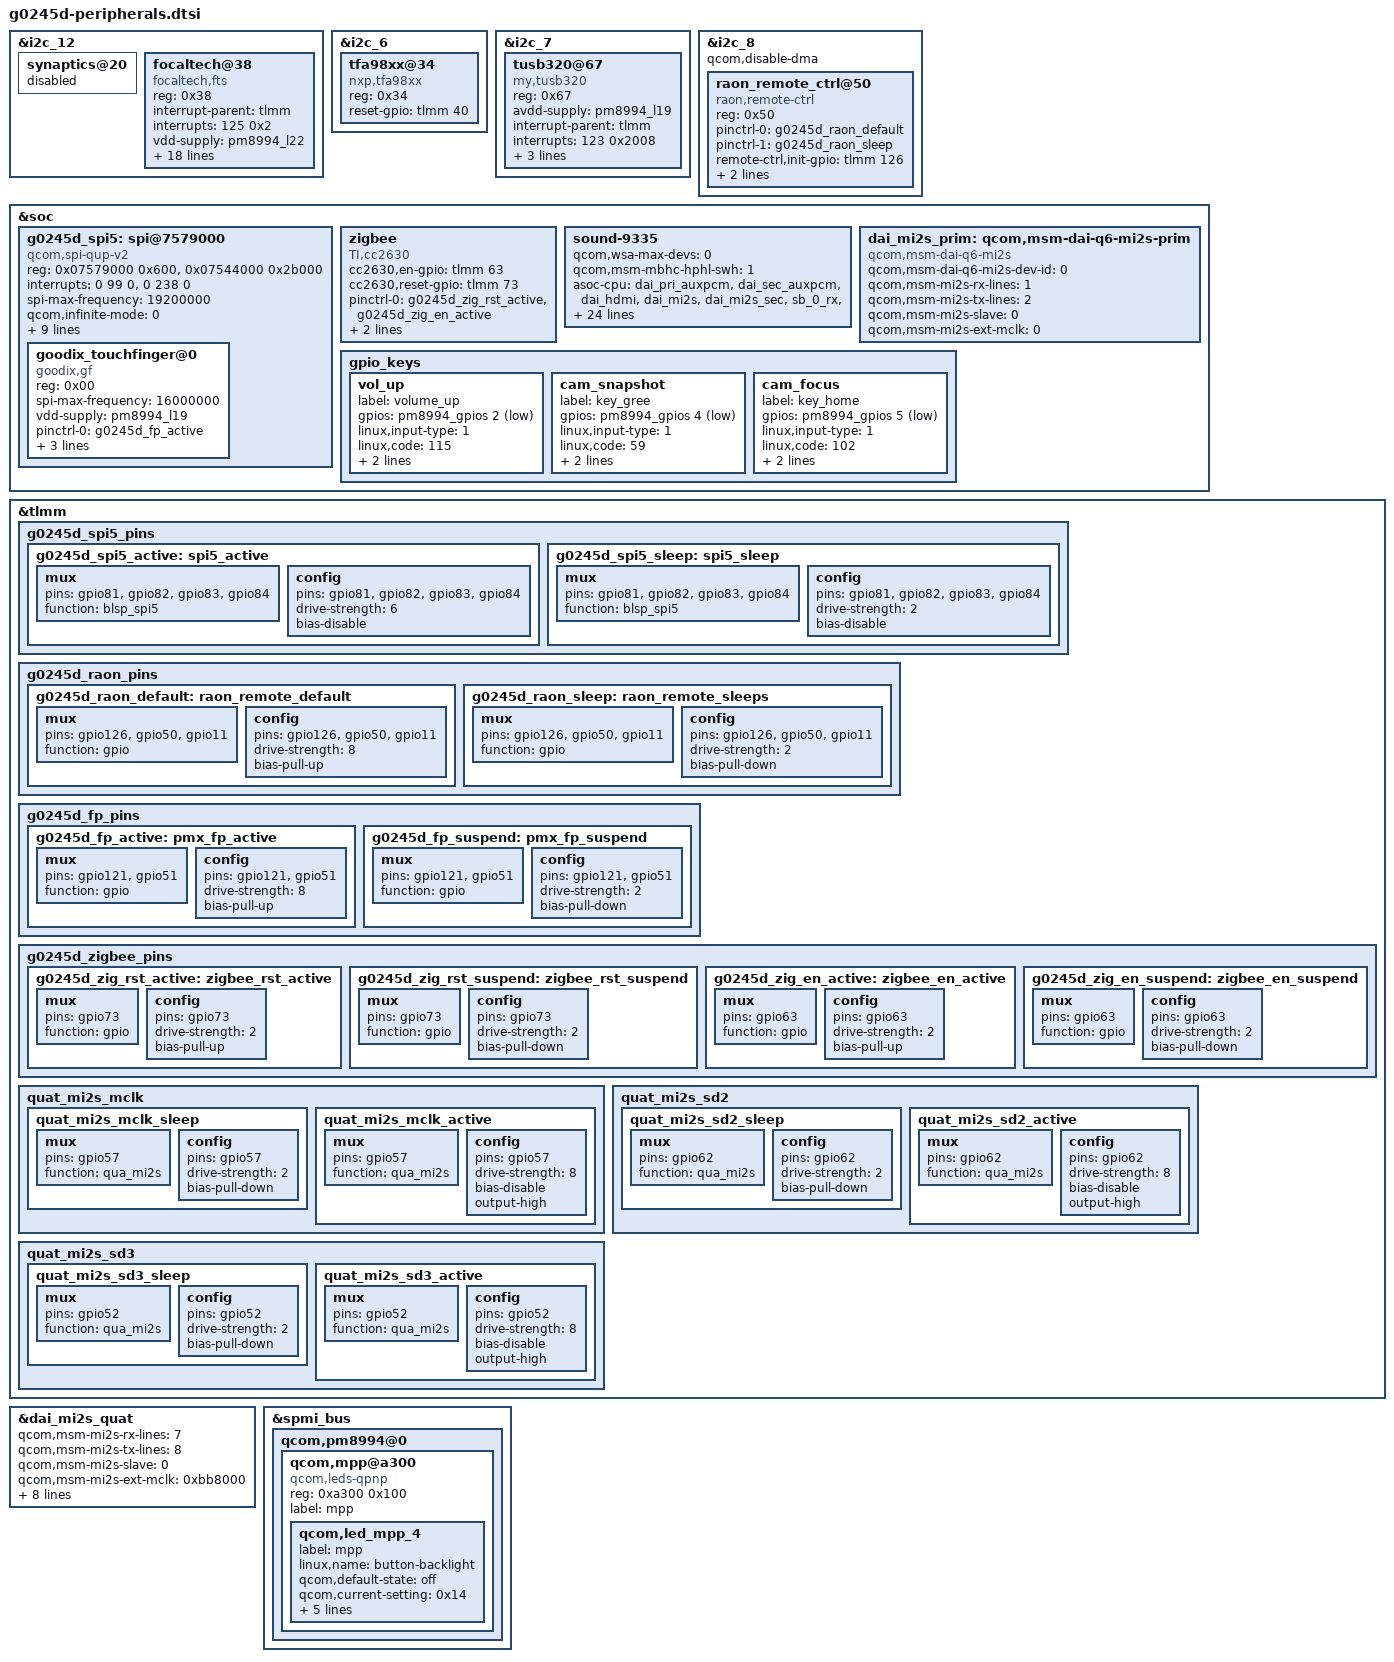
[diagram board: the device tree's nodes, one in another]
/*
 * Gree G0245D private peripheral device-tree nodes.
 *
 * Contract source: work/stock-044.dts (the DTB actually selected by the
 * G0245D bootloader) and 3.18/kernel-g0245d-cm13/Documentation/g0245d/
 * peripherals.md.  Numeric phandles were resolved to 4.4 labels; the
 * pinctrl states are newly declared here because the 4.4 MTP dtsi only
 * carries ts_active/ts_suspend.
 *
 * This file is purely additive: it never overrides a panel or WLAN node.
 */

&i2c_12 {
	/* The inherited 4.4 MTP dtsi declares a Synaptics DSX touch at 0x20 on
	 * this bus, and mi8996_defconfig enables that driver. G0245D only has
	 * the FT8716 at 0x38; both nodes would otherwise claim GPIO 125 for the
	 * touch IRQ. Disable it here so the upstream dtsi stays untouched.
	 */
	synaptics@20 {
		status = "disabled";
	};

	focaltech@38 {
		compatible = "focaltech,fts";
		reg = <0x38>;
		interrupt-parent = <&tlmm>;
		interrupts = <125 0x2>;
		vdd-supply = <&pm8994_l22>;
		vcc_i2c-supply = <&pm8994_l14>;
		pinctrl-names = "pmx_ts_active", "pmx_ts_suspend";
		pinctrl-0 = <&ts_active>;
		pinctrl-1 = <&ts_suspend>;
		focaltech,name = "fts";
		focaltech,family-id = <0x54>;
		focaltech,reset-gpio = <&tlmm 89 0x00>;
		focaltech,irq-gpio = <&tlmm 125 0x02>;
		focaltech,display-coords = <0 0 1080 1920>;
		focaltech,panel-coords = <0 0 1080 1920>;
		focaltech,button-map = <0x46 0x96 0x38b>;
		focaltech,no-force-update;
		focaltech,i2c-pull-up;
		focaltech,group-id = <0x01>;
		focaltech,hard-reset-delay-ms = <0x14>;
		focaltech,soft-reset-delay-ms = <0x96>;
		focaltech,num-max-touches = <0x0a>;
		focaltech,fw-name = "FT8716_FW_Reference_V0A_D01_20170227_app.i";
	};
};

&i2c_6 {
	/* The baseline SND_SOC_TFA98XX codec driver (force-selected by
	 * sound/soc/msm/Kconfig) matches "tfa,tfa98xx".  The stock string is
	 * kept first so the 3.18 reconstruction could still bind if ever built.
	 */
	tfa98xx@34 {
		compatible = "nxp,tfa98xx", "tfa,tfa98xx";
		reg = <0x34>;
		reset-gpio = <&tlmm 40 0x00>;
		/* gpio13 must stay free: it is CAMIF_MCLK0 for the rear
		 * IMX258 (stock camera@0 gpios[0] = tlmm 13). A previous
		 * audio test wired it as a speaker amp-enable here, which
		 * made msm_camera_request_gpio_table fail on MCLK0 and the
		 * rear sensor never powered up. Stock defines no amp-enable
		 * at all; speaker gating goes through qcom,spkr-sd-n-gpio
		 * (pm8994 GPIOs) instead. Re-verify speaker audio after
		 * removing this. */
	};
};

&i2c_7 {
	tusb320@67 {
		compatible = "my,tusb320";
		reg = <0x67>;
		avdd-supply = <&pm8994_l19>;
		interrupt-parent = <&tlmm>;
		interrupts = <123 0x2008>;
		tusb320,irq-gpio = <&tlmm 123 0x2008>;
		tusb320,select-gpio = <&tlmm 92 0x00>;
		tusb320,enable-gpio = <&tlmm 47 0x00>;
	};
};

&i2c_8 {
	/* Raon IR frames exceed the FIFO; 4.4 i2c-msm-v2 DMA reports
	 * OVER_UNDER_RUN for them.  BLOCK mode is the stock-compatible path. */
	qcom,disable-dma;

	raon_remote_ctrl@50 {
		compatible = "raon,remote-ctrl";
		reg = <0x50>;
		pinctrl-names = "raon_remote_default", "raon_remote_sleeps";
		pinctrl-0 = <&g0245d_raon_default>;
		pinctrl-1 = <&g0245d_raon_sleep>;
		remote-ctrl,init-gpio = <&tlmm 126 0x00>;
		remote-ctrl,reset-gpio = <&tlmm 11 0x00>;
		remote-ctrl,en-gpio = <&tlmm 50 0x00>;
	};
};

/* BLSP1 QUP5 SPI controller at 0x7579000 is absent from the 4.4 msm8996
 * dtsi but present in the G0245D stock DTB. Clocks are the 4.4 bindings:
 *   clk_gcc_blsp1_ahb_clk           = 0x8caa5b4f
 *   clk_gcc_blsp1_qup5_spi_apps_clk = 0xbf3e15d7
 * which are exactly the two clock phandle values in stock-044.dts.
 */
&soc {
	g0245d_spi5: spi@7579000 {
		compatible = "qcom,spi-qup-v2";
		#address-cells = <1>;
		#size-cells = <0>;
		reg-names = "spi_physical", "spi_bam_physical";
		reg = <0x07579000 0x600>, <0x07544000 0x2b000>;
		interrupt-names = "spi_irq", "spi_bam_irq";
		interrupts = <0 99 0>, <0 238 0>;
		spi-max-frequency = <19200000>;
		qcom,infinite-mode = <0>;
		qcom,ver-reg-exists;
		qcom,bam-consumer-pipe-index = <20>;
		qcom,bam-producer-pipe-index = <21>;
		qcom,master-id = <86>;
		qcom,use-pinctrl;
		pinctrl-names = "spi_default", "spi_sleep";
		pinctrl-0 = <&g0245d_spi5_active>;
		pinctrl-1 = <&g0245d_spi5_sleep>;
		clock-names = "iface_clk", "core_clk";
		clocks = <&clock_gcc clk_gcc_blsp1_ahb_clk>,
			 <&clock_gcc clk_gcc_blsp1_qup5_spi_apps_clk>;
		status = "ok";

		goodix_touchfinger@0 {
			compatible = "goodix,gf";
			reg = <0x00>;
			spi-max-frequency = <16000000>;
			vdd-supply = <&pm8994_l19>;
			pinctrl-names = "pmx_fp_active", "pmx_fp_suspend";
			pinctrl-0 = <&g0245d_fp_active>;
			pinctrl-1 = <&g0245d_fp_suspend>;
			goodix,spi_irq_gpio = <&tlmm 121 0x2008>;
			goodix,spi_reset_gpio = <&tlmm 51 0x00>;
		};
	};

	zigbee {
		compatible = "TI,cc2630";
		cc2630,en-gpio = <&tlmm 63 0x00>;
		cc2630,reset-gpio = <&tlmm 73 0x00>;
		pinctrl-names = "zigbee_active", "zigbee_suspend";
		pinctrl-0 = <&g0245d_zig_rst_active &g0245d_zig_en_active>;
		pinctrl-1 = <&g0245d_zig_rst_suspend &g0245d_zig_en_suspend>;
	};
};

&tlmm {
	g0245d_spi5_pins {
		/* BLSP1 QUP5 SPI: mosi/miso/cs/clk = gpio81..gpio84 (pinctrl-msm8996.c
		 * blsp_spi5_groups). Without muxing the QUP Tx times out ("SPI Tx
		 * transaction timeout" on the first chip-id read). */
		g0245d_spi5_active: spi5_active {
			mux {
				pins = "gpio81", "gpio82", "gpio83", "gpio84";
				function = "blsp_spi5";
			};
			config {
				pins = "gpio81", "gpio82", "gpio83", "gpio84";
				drive-strength = <6>;
				bias-disable;
			};
		};

		g0245d_spi5_sleep: spi5_sleep {
			mux {
				pins = "gpio81", "gpio82", "gpio83", "gpio84";
				function = "blsp_spi5";
			};
			config {
				pins = "gpio81", "gpio82", "gpio83", "gpio84";
				drive-strength = <2>;
				bias-disable;
			};
		};
	};

	g0245d_raon_pins {
		g0245d_raon_default: raon_remote_default {
			mux {
				pins = "gpio126", "gpio50", "gpio11";
				function = "gpio";
			};
			config {
				pins = "gpio126", "gpio50", "gpio11";
				drive-strength = <8>;
				bias-pull-up;
			};
		};

		g0245d_raon_sleep: raon_remote_sleeps {
			mux {
				pins = "gpio126", "gpio50", "gpio11";
				function = "gpio";
			};
			config {
				pins = "gpio126", "gpio50", "gpio11";
				drive-strength = <2>;
				bias-pull-down;
			};
		};
	};

	g0245d_fp_pins {
		g0245d_fp_active: pmx_fp_active {
			mux {
				pins = "gpio121", "gpio51";
				function = "gpio";
			};
			config {
				pins = "gpio121", "gpio51";
				drive-strength = <8>;
				bias-pull-up;
			};
		};

		g0245d_fp_suspend: pmx_fp_suspend {
			mux {
				pins = "gpio121", "gpio51";
				function = "gpio";
			};
			config {
				pins = "gpio121", "gpio51";
				drive-strength = <2>;
				bias-pull-down;
			};
		};
	};

	g0245d_zigbee_pins {
		g0245d_zig_rst_active: zigbee_rst_active {
			mux {
				pins = "gpio73";
				function = "gpio";
			};
			config {
				pins = "gpio73";
				drive-strength = <2>;
				bias-pull-up;
			};
		};

		g0245d_zig_rst_suspend: zigbee_rst_suspend {
			mux {
				pins = "gpio73";
				function = "gpio";
			};
			config {
				pins = "gpio73";
				drive-strength = <2>;
				bias-pull-down;
			};
		};

		g0245d_zig_en_active: zigbee_en_active {
			mux {
				pins = "gpio63";
				function = "gpio";
			};
			config {
				pins = "gpio63";
				drive-strength = <2>;
				bias-pull-up;
			};
		};

		g0245d_zig_en_suspend: zigbee_en_suspend {
			mux {
				pins = "gpio63";
				function = "gpio";
			};
			config {
				pins = "gpio63";
				drive-strength = <2>;
				bias-pull-down;
			};
		};
	};
};

/* G0245D uses a TFA9890 I2C smart amp (i2c_6, see above), NOT WSA881x. The
 * inherited MTP sound node sets qcom,wsa-max-devs = <2> and references the
 * WSA881x codec devices, which are absent on this board; their probe fails
 * with -22 and blocks ASoC card registration ("No soundcards found").
 * Disable WSA to match the known-good CM13 (3.18) audio config so the
 * Tasha/WCD9335 card registers and routes to the TFA9890 via "hifi amp". */
&soc {
	sound-9335 {
		qcom,wsa-max-devs = <0>;
		/* Stock G0245D DTB (msm-id 0xf6/0x30001, board 0x08/0x00,
		 * pmic 0x20009/0x10013) carries hphl-swh=1; the inherited
		 * msm8996.dtsi default (0) leaves MBHC falsely reporting a
		 * headset insert at boot, which sends every playback route
		 * to the (not wired) headset instead of the speaker. */
		qcom,msm-mbhc-hphl-swh = <1>;
		/* CM13 (3.18) G0245D has no TDM BE dai_links: msm8996-mtp.dtsi
		 * there does not set qcom,tdm-audio-intf.  The 4.4 CAF dtsi
		 * sets it, pulling in msm8996_tdm_be_dai_links whose 32 TDM
		 * cpu_dai_names ("msm-dai-q6-tdm.36xxx") can never bind on
		 * this board and would block the whole Tasha card, so drop
		 * the property to restore the CM13 link set.
		 * Also drop qcom,hdmi-audio-rx.  CM13 kept it, but there the
		 * ext-disp audio codec registered; in 4.4 that path needs
		 * FB_MSM_MDSS_HDMI_PANEL + MSM_EXT_DISPLAY + the ext-disp
		 * codec, and enabling the 4.4 HDMI TX panel driver
		 * boot-loops this board (panic at USB/MTP enumeration,
		 * verified on device).  The HDMI BE link is unused for this
		 * board's speaker/headset playback, so remove it instead. */
		/delete-property/ qcom,tdm-audio-intf;
		/delete-property/ qcom,hdmi-audio-rx;
	};
};

/* G0245D audio: the TFA9890 hangs off quaternary MI2S, driven with an
 * external 12.288 MHz MCLK and all four data lines (3 RX, 1 TX), and the
 * qua_mi2s pins must be muxed for playback to reach the amp.  The 4.4 CAF
 * dtsi quat node has upstream's bare-bones values (rx-lines=1, tx-lines=0,
 * no MCLK/pinctrl), which the ADSP rejects at AFE port start
 * ("afe_send_cmd_port_start: AFE enable for port 0x4000 failed").
 * Restore the property set and pin configuration of the known-good CM13
 * (3.18) G0245D DTB.  The 4.4 pinctrl dtsi already carries the sclk/ws
 * (gpio58/59), sd0 (gpio60) and sd1 (gpio61) groups; add the missing
 * mclk (gpio57), sd2 (gpio62) and sd3 (gpio52) groups below and wire all
 * of them to the DAI node.
 */
&tlmm {
	quat_mi2s_mclk {
		quat_mi2s_mclk_sleep: quat_mi2s_mclk_sleep {
			mux {
				pins = "gpio57";
				function = "qua_mi2s";
			};
			config {
				pins = "gpio57";
				drive-strength = <2>;
				bias-pull-down;
			};
		};
		quat_mi2s_mclk_active: quat_mi2s_mclk_active {
			mux {
				pins = "gpio57";
				function = "qua_mi2s";
			};
			config {
				pins = "gpio57";
				drive-strength = <8>;
				bias-disable;
				output-high;
			};
		};
	};

	quat_mi2s_sd2 {
		quat_mi2s_sd2_sleep: quat_mi2s_sd2_sleep {
			mux {
				pins = "gpio62";
				function = "qua_mi2s";
			};
			config {
				pins = "gpio62";
				drive-strength = <2>;
				bias-pull-down;
			};
		};
		quat_mi2s_sd2_active: quat_mi2s_sd2_active {
			mux {
				pins = "gpio62";
				function = "qua_mi2s";
			};
			config {
				pins = "gpio62";
				drive-strength = <8>;
				bias-disable;
				output-high;
			};
		};
	};

	quat_mi2s_sd3 {
		quat_mi2s_sd3_sleep: quat_mi2s_sd3_sleep {
			mux {
				pins = "gpio52";
				function = "qua_mi2s";
			};
			config {
				pins = "gpio52";
				drive-strength = <2>;
				bias-pull-down;
			};
		};
		quat_mi2s_sd3_active: quat_mi2s_sd3_active {
			mux {
				pins = "gpio52";
				function = "qua_mi2s";
			};
			config {
				pins = "gpio52";
				drive-strength = <8>;
				bias-disable;
				output-high;
			};
		};
	};
};

&dai_mi2s_quat {
	qcom,msm-mi2s-rx-lines = <7>;
	qcom,msm-mi2s-tx-lines = <8>;
	qcom,msm-mi2s-slave = <0>;
	qcom,msm-mi2s-ext-mclk = <0xbb8000>;
	pinctrl-names = "default", "idle";
	pinctrl-0 = <&quat_mi2s_active>, <&quat_mi2s_mclk_active>,
			<&quat_mi2s_sd0_active>, <&quat_mi2s_sd1_active>,
			<&quat_mi2s_sd2_active>, <&quat_mi2s_sd3_active>;
	pinctrl-1 = <&quat_mi2s_sleep>, <&quat_mi2s_mclk_sleep>,
			<&quat_mi2s_sd0_sleep>, <&quat_mi2s_sd1_sleep>,
			<&quat_mi2s_sd2_sleep>, <&quat_mi2s_sd3_sleep>;
};

/* G0245D audio: the 4.4 CAF dtsi dropped the legacy primary MI2S DAI node
 * (it only kept sec/tert/quat and added the group-mi2s form), so the
 * machine driver's PRI_MI2S dai_links bind against "msm-dai-q6-mi2s.0",
 * a DAI that never registers: "ASoC: CPU DAI msm-dai-q6-mi2s.0 not
 * registered" blocks the whole Tasha sound card.  Restore the primary
 * MI2S node with exactly the property set of the known-good CM13 (3.18)
 * G0245D DTB. */
&soc {
	dai_mi2s_prim: qcom,msm-dai-q6-mi2s-prim {
		compatible = "qcom,msm-dai-q6-mi2s";
		qcom,msm-dai-q6-mi2s-dev-id = <0>;
		qcom,msm-mi2s-rx-lines = <1>;
		qcom,msm-mi2s-tx-lines = <2>;
		qcom,msm-mi2s-slave = <0>;
		qcom,msm-mi2s-ext-mclk = <0>;
	};
};

/* G0245D audio: 4.4 soc-core names these legacy MI2S DAIs after the DT
 * device node ("soc:qcom,msm-dai-q6-mi2s-prim") instead of the 3.18-style
 * "msm-dai-q6-mi2s.N", so string matching in soc_bind_dai_link can never
 * succeed.  The upstream workaround is DT-side: listing the cpu dai in
 * asoc-cpu/asoc-cpu-names makes the machine driver populate cpu_of_node
 * and drop cpu_dai_name, so the bind runs on of_node only.  The baseline
 * list has 28 entries and lacks the primary (id 0), secondary (id 1) and
 * quaternary (id 3, TFA9890) MI2S dais; re-declare the full list plus
 * those three entries. */
&soc {
	sound-9335 {
		asoc-cpu = <&dai_pri_auxpcm>, <&dai_sec_auxpcm>, <&dai_hdmi>, <&dai_mi2s>,
				<&dai_mi2s_sec>,
				<&sb_0_rx>, <&sb_0_tx>, <&sb_1_rx>, <&sb_1_tx>,
				<&sb_2_rx>, <&sb_2_tx>, <&sb_3_rx>, <&sb_3_tx>,
				<&sb_4_rx>, <&sb_4_tx>, <&sb_5_tx>, <&afe_pcm_rx>,
				<&afe_pcm_tx>, <&afe_proxy_rx>, <&afe_proxy_tx>,
				<&incall_record_rx>, <&incall_record_tx>,
				<&incall_music_rx>, <&incall_music2_rx>,
				<&sb_5_rx>, <&sb_6_rx>,
				<&usb_audio_rx>, <&usb_audio_tx>,
				<&dai_mi2s_prim>, <&dai_mi2s_quat>;
		asoc-cpu-names = "msm-dai-q6-auxpcm.1", "msm-dai-q6-auxpcm.2",
				"msm-dai-q6-hdmi.8", "msm-dai-q6-mi2s.2",
				"msm-dai-q6-mi2s.1",
				"msm-dai-q6-dev.16384", "msm-dai-q6-dev.16385",
				"msm-dai-q6-dev.16386", "msm-dai-q6-dev.16387",
				"msm-dai-q6-dev.16388", "msm-dai-q6-dev.16389",
				"msm-dai-q6-dev.16390", "msm-dai-q6-dev.16391",
				"msm-dai-q6-dev.16392", "msm-dai-q6-dev.16393",
				"msm-dai-q6-dev.16395", "msm-dai-q6-dev.224",
				"msm-dai-q6-dev.225", "msm-dai-q6-dev.241",
				"msm-dai-q6-dev.240", "msm-dai-q6-dev.32771",
				"msm-dai-q6-dev.32772", "msm-dai-q6-dev.32773",
				"msm-dai-q6-dev.32770", "msm-dai-q6-dev.16394",
				"msm-dai-q6-dev.16396",
				"msm-dai-q6-dev.28672", "msm-dai-q6-dev.28673",
				"msm-dai-q6-mi2s.0", "msm-dai-q6-mi2s.3";
	};
};

/* Physical keys: stock DTB (d44) wires PM8994 GPIO 5 as the front Home
 * switch (linux,code 102) and GPIO 4 as the extra Gree key (59). The
 * msm8996-mtp.dtsi baseline keeps the MTP camera codes (766/528) which map
 * to dead CAMERA/FOCUS keycodes on Android, so override with stock values.
 * The baseline node lives under &soc (msm8996-mtp.dtsi:642); override there
 * so the merge lands on /soc/gpio_keys, not a stray root-level node.
 * Node names are kept identical to the baseline for property-level merge. */
&soc {
	gpio_keys {
		vol_up {
			label = "volume_up";
			gpios = <&pm8994_gpios 2 0x1>;
			linux,input-type = <1>;
			linux,code = <115>;
			gpio-key,wakeup;
			debounce-interval = <30>;
		};

		cam_snapshot {
			label = "key_gree";
			gpios = <&pm8994_gpios 4 0x1>;
			linux,input-type = <1>;
			linux,code = <59>;
			gpio-key,wakeup;
			debounce-interval = <30>;
		};

		cam_focus {
			label = "key_home";
			gpios = <&pm8994_gpios 5 0x1>;
			linux,input-type = <1>;
			linux,code = <102>;
			gpio-key,wakeup;
			debounce-interval = <30>;
		};
	};
};

/* G0245D capacitive touch-key backlight (Back / Recents).
 *
 * Stock DTB (work/stock-dtb/stock-44-off1617434.dts, under
 * qcom,pm8994@0) drives these two keys from PM8994 MPP4 through a
 * dedicated qcom,leds-qpnp node called "qcom,mpp@a300" (reg 0xa300)
 * whose child declares linux,name = "button-backlight".  The inherited
 * msm8996-mtp.dtsi only exposes the same physical MPP4 as an
 * HDMI_5v_vreg GPIO (mpp@a300 under pm8994_mpps).  Stock intentionally
 * keeps BOTH nodes -- qpnp-pin and qcom,leds-qpnp share the regmap --
 * so add the LED node alongside it instead of disabling the GPIO node.
 *
 * Stock also sets linux,default-trigger = "hr-trigger", but this 4.4
 * kernel has no hr-trigger driver.  Leave the trigger unset; the
 * "manual" mode lets the AOSP lights HAL drive brightness directly
 * via /sys/class/leds/button-backlight/brightness (init.g0245d.rc and
 * ueventd.qcom.rc already declare that node's permissions).
 */
&spmi_bus {
	qcom,pm8994@0 {
		qcom,mpp@a300 {
			compatible = "qcom,leds-qpnp";
			reg = <0xa300 0x100>;
			label = "mpp";
			status = "okay";

			qcom,led_mpp_4 {
				label = "mpp";
				linux,name = "button-backlight";
				qcom,default-state = "off";
				qcom,current-setting = <0x14>;
				qcom,max-current = <0x28>;
				qcom,id = <0x06>;
				qcom,source-sel = <0x01>;
				qcom,mode-ctrl = <0x60>;
				qcom,mode = "manual";
			};
		};
	};
};
